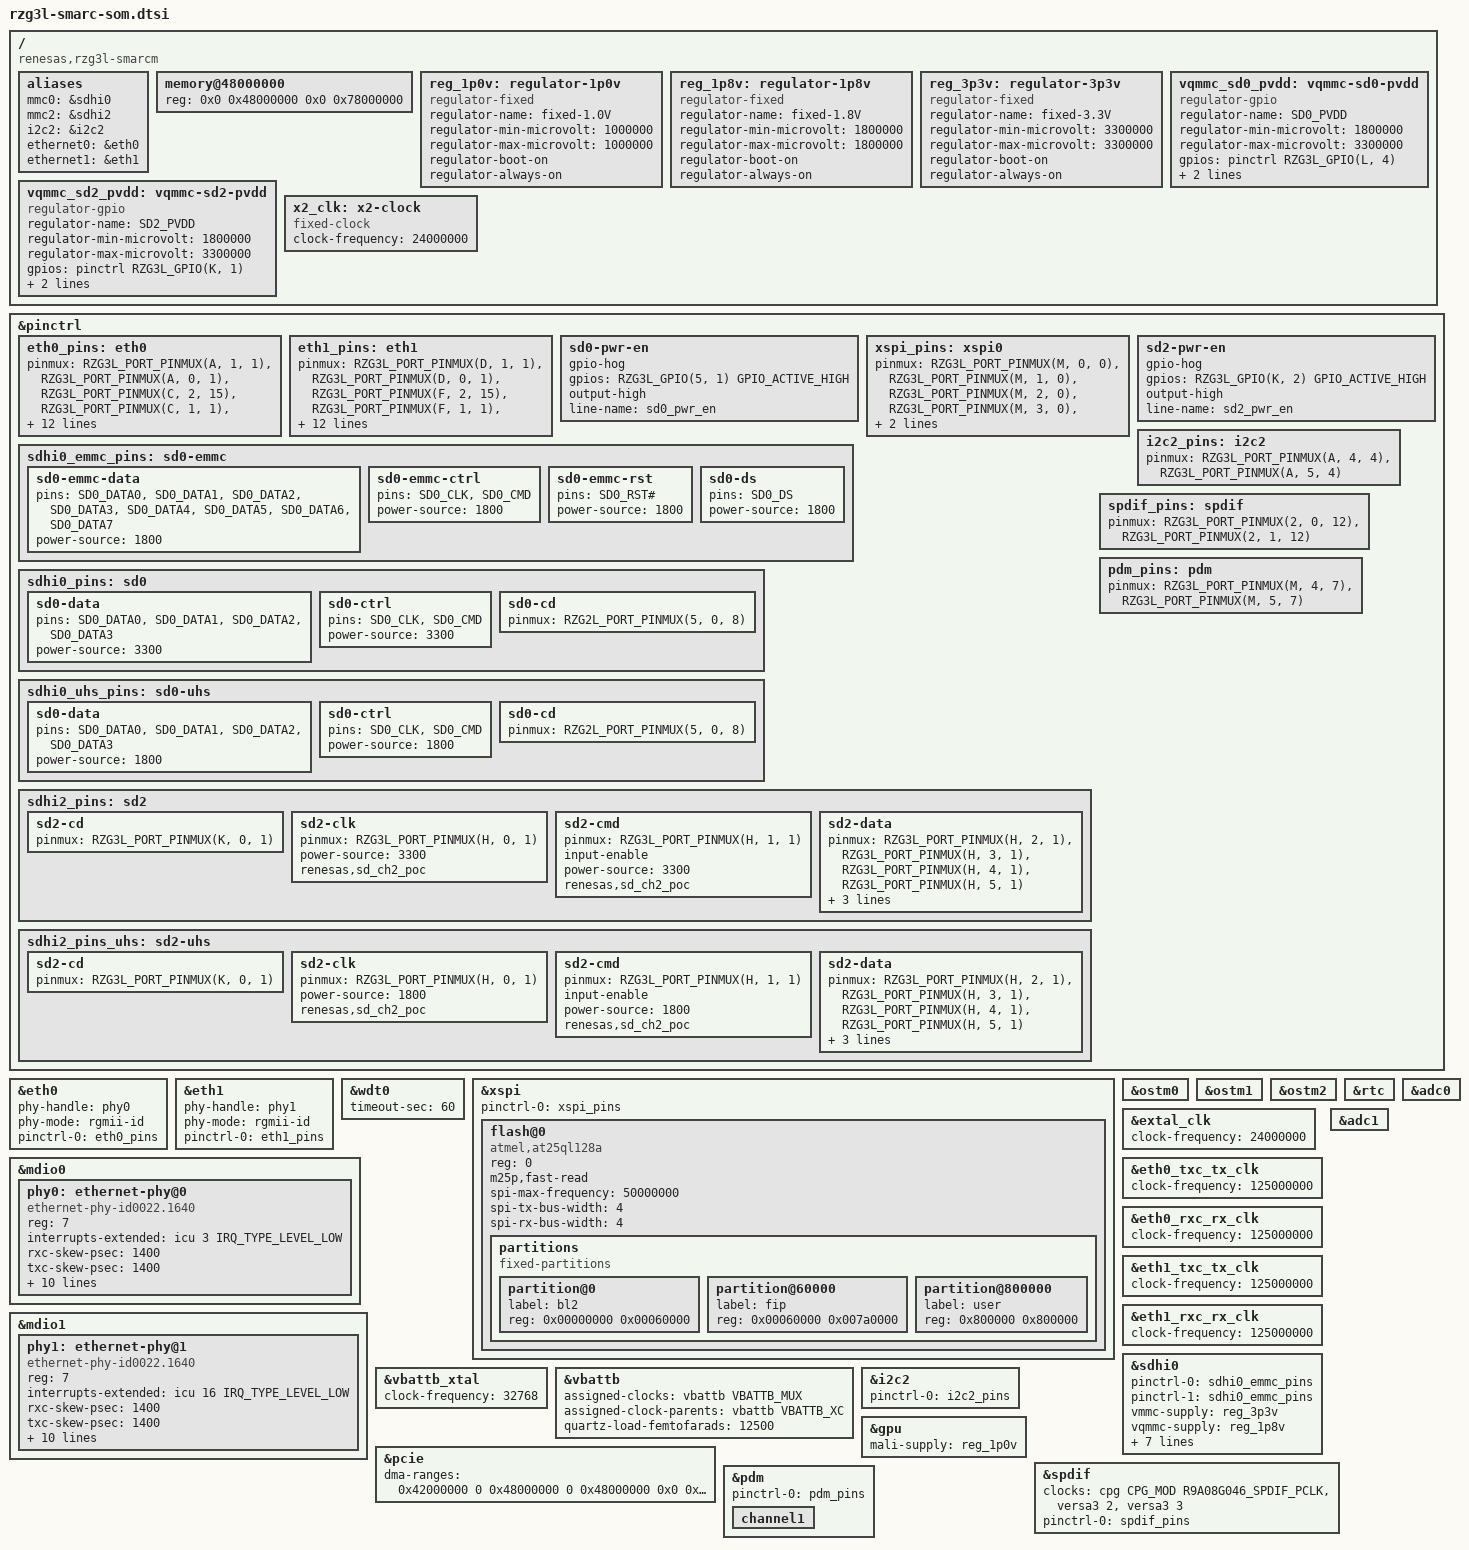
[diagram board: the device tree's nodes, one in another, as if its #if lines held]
// SPDX-License-Identifier: (GPL-2.0-only OR BSD-2-Clause)
/*
 * Device Tree Source for R9A08G046L68 SMARC SoM board.
 *
 * Copyright (C) 2025 Renesas Electronics Corp.
 */

/*
 * Please set the below switch position on the SoM and the corresponding macro
 * on the board DTS:
 *
 * Switch position SYS.1, Macro SW_SD0_DEV_SEL:
 *      0 - SD0 is connected to eMMC (default)
 *      1 - SD0 is connected to uSD0 card
 *
 * Switch position SYS.5, Macro SW_DPI_EN:
 *      0 - Select Misc. Signals routing
 *      1 - Select LCD
 */

#include <dt-bindings/clock/renesas,r9a08g046-vbattb.h>

/ {
	compatible = "renesas,rzg3l-smarcm", "renesas,r9a08g046l48", "renesas,r9a08g046";

	aliases {
		mmc0 = &sdhi0;
		mmc2 = &sdhi2;
		i2c2 = &i2c2;
		ethernet0 = &eth0;
		ethernet1 = &eth1;
	};

	memory@48000000 {
		device_type = "memory";
		/* First 128MB is reserved for secure area. */
		reg = <0x0 0x48000000 0x0 0x78000000>;
	};

	reg_1p0v: regulator-1p0v {
		compatible = "regulator-fixed";
		regulator-name = "fixed-1.0V";
		regulator-min-microvolt = <1000000>;
		regulator-max-microvolt = <1000000>;
		regulator-boot-on;
		regulator-always-on;
	};

	reg_1p8v: regulator-1p8v {
		compatible = "regulator-fixed";
		regulator-name = "fixed-1.8V";
		regulator-min-microvolt = <1800000>;
		regulator-max-microvolt = <1800000>;
		regulator-boot-on;
		regulator-always-on;
	};

	reg_3p3v: regulator-3p3v {
		compatible = "regulator-fixed";
		regulator-name = "fixed-3.3V";
		regulator-min-microvolt = <3300000>;
		regulator-max-microvolt = <3300000>;
		regulator-boot-on;
		regulator-always-on;
	};

#if SW_SD0_DEV_SEL
	vqmmc_sd0_pvdd: vqmmc-sd0-pvdd {
		compatible = "regulator-gpio";
		regulator-name = "SD0_PVDD";
		regulator-min-microvolt = <1800000>;
		regulator-max-microvolt = <3300000>;
		gpios = <&pinctrl RZG3L_GPIO(L, 4) GPIO_ACTIVE_HIGH>;
		gpios-states = <0>;
		states = <3300000 0>, <1800000 1>;
	};
#endif

#if SW_SD2_DEV_SEL
        vqmmc_sd2_pvdd: vqmmc-sd2-pvdd {
		compatible = "regulator-gpio";
		regulator-name = "SD2_PVDD";
		regulator-min-microvolt = <1800000>;
		regulator-max-microvolt = <3300000>;
		gpios = <&pinctrl RZG3L_GPIO(K, 1) GPIO_ACTIVE_HIGH>;
		gpios-states = <0>;
		states = <3300000 0>, <1800000 1>;
	};
#endif

	x2_clk: x2-clock {
		compatible = "fixed-clock";
		#clock-cells = <0>;
		clock-frequency = <24000000>;
	};
};

&pinctrl {
	eth0_pins: eth0 {
		pinmux = <RZG3L_PORT_PINMUX(A, 1, 1)>, /* MDC */
			 <RZG3L_PORT_PINMUX(A, 0, 1)>, /* MDIO */
			 <RZG3L_PORT_PINMUX(C, 2, 15)>, /* PHY_INTR */
			 <RZG3L_PORT_PINMUX(C, 1, 1)>, /* RXD3 */
			 <RZG3L_PORT_PINMUX(C, 0, 1)>, /* RXD2 */
			 <RZG3L_PORT_PINMUX(B, 7, 1)>, /* RXD1 */
			 <RZG3L_PORT_PINMUX(B, 6, 1)>, /* RXD0 */
			 <RZG3L_PORT_PINMUX(B, 0, 1)>, /* RXC */
			 <RZG3L_PORT_PINMUX(A, 2, 1)>, /* RX_CTL */
			 <RZG3L_PORT_PINMUX(B, 5, 1)>, /* TXD3 */
			 <RZG3L_PORT_PINMUX(B, 4, 1)>, /* TXD2 */
			 <RZG3L_PORT_PINMUX(B, 3, 1)>, /* TXD1 */
			 <RZG3L_PORT_PINMUX(B, 2, 1)>, /* TXD0 */
			 <RZG3L_PORT_PINMUX(B, 1, 1)>, /* TXC */
			 <RZG3L_PORT_PINMUX(A, 3, 1)>; /* TX_CTL */
			 power-source = <1800>;
	};

	eth1_pins: eth1 {
		pinmux = <RZG3L_PORT_PINMUX(D, 1, 1)>, /* MDC */
			 <RZG3L_PORT_PINMUX(D, 0, 1)>, /* MDIO */
			 <RZG3L_PORT_PINMUX(F, 2, 15)>, /* PHY_INTR */
			 <RZG3L_PORT_PINMUX(F, 1, 1)>, /* RXD3 */
			 <RZG3L_PORT_PINMUX(F, 0, 1)>, /* RXD2 */
			 <RZG3L_PORT_PINMUX(E, 7, 1)>, /* RXD1 */
			 <RZG3L_PORT_PINMUX(E, 6, 1)>, /* RXD0 */
			 <RZG3L_PORT_PINMUX(E, 0, 1)>, /* RXC */
			 <RZG3L_PORT_PINMUX(D, 2, 1)>, /* RX_CTL */
			 <RZG3L_PORT_PINMUX(E, 5, 1)>, /* TXD3 */
			 <RZG3L_PORT_PINMUX(E, 4, 1)>, /* TXD2 */
			 <RZG3L_PORT_PINMUX(E, 3, 1)>, /* TXD1 */
			 <RZG3L_PORT_PINMUX(E, 2, 1)>, /* TXD0 */
			 <RZG3L_PORT_PINMUX(E, 1, 1)>, /* TXC */
			 <RZG3L_PORT_PINMUX(D, 3, 1)>; /* TX_CTL */
			 power-source = <1800>;
	};

#if (!SW_DPI_EN)
	sd0-pwr-en {
		gpio-hog;
		gpios = <RZG3L_GPIO(5, 1) GPIO_ACTIVE_HIGH>;
		output-high;
		line-name = "sd0_pwr_en";
	};
#endif

	xspi_pins: xspi0 {
		pinmux = <RZG3L_PORT_PINMUX(M, 0, 0)>, /* XSPI0_IO0 */
			 <RZG3L_PORT_PINMUX(M, 1, 0)>, /* XSPI0_IO1 */
			 <RZG3L_PORT_PINMUX(M, 2, 0)>, /* XSPI0_IO2 */
			 <RZG3L_PORT_PINMUX(M, 3, 0)>, /* XSPI0_IO3 */
			 <RZG3L_PORT_PINMUX(L, 0, 0)>, /* XSPI0_CKP */
			 <RZG3L_PORT_PINMUX(L, 1, 0)>; /* XSPI0_CS0 */
	};

	sdhi0_emmc_pins: sd0-emmc {
		sd0-emmc-data {
			pins = "SD0_DATA0", "SD0_DATA1", "SD0_DATA2", "SD0_DATA3",
			       "SD0_DATA4", "SD0_DATA5", "SD0_DATA6", "SD0_DATA7";
			power-source = <1800>;
		};

		sd0-emmc-ctrl {
			pins = "SD0_CLK", "SD0_CMD";
			power-source = <1800>;
		};

		sd0-emmc-rst {
			pins = "SD0_RST#";
			power-source = <1800>;
		};

		sd0-ds {
			pins = "SD0_DS";
			power-source = <1800>;
		};
	};

	sdhi0_pins: sd0 {
		sd0-data {
			pins = "SD0_DATA0", "SD0_DATA1", "SD0_DATA2", "SD0_DATA3";
			power-source = <3300>;
		};

		sd0-ctrl {
			pins = "SD0_CLK", "SD0_CMD";
			power-source = <3300>;
		};

		sd0-cd {
			pinmux = <RZG2L_PORT_PINMUX(5, 0, 8)>; /* SD0_CD */
		};
	};

	sdhi0_uhs_pins: sd0-uhs {
		sd0-data {
			pins = "SD0_DATA0", "SD0_DATA1", "SD0_DATA2", "SD0_DATA3";
			power-source = <1800>;
		};

		sd0-ctrl {
			pins = "SD0_CLK", "SD0_CMD";
			power-source = <1800>;
		};

		sd0-cd {
			pinmux = <RZG2L_PORT_PINMUX(5, 0, 8)>; /* SD0_CD */
		};
	};

#if (SW_SD2_DEV_SEL)
	sd2-pwr-en {
		gpio-hog;
		gpios = <RZG3L_GPIO(K, 2) GPIO_ACTIVE_HIGH>;
		output-high;
		line-name = "sd2_pwr_en";
	};

	sdhi2_pins: sd2 {
		sd2-cd {
			pinmux = <RZG3L_PORT_PINMUX(K, 0, 1)>; /* SD2_CD */
		};

		sd2-clk {
			pinmux = <RZG3L_PORT_PINMUX(H, 0, 1)>; /* SD2_CLK */
			power-source = <3300>;
			renesas,sd_ch2_poc;
		};

		sd2-cmd {
			pinmux = <RZG3L_PORT_PINMUX(H, 1, 1)>; /* SD2_CMD */
			input-enable;
			power-source = <3300>;
			renesas,sd_ch2_poc;
		};

		sd2-data {
			pinmux = <RZG3L_PORT_PINMUX(H, 2, 1)>, /* SD2_DAT0 */
				 <RZG3L_PORT_PINMUX(H, 3, 1)>, /* SD2_DAT1 */
				 <RZG3L_PORT_PINMUX(H, 4, 1)>, /* SD2_DAT2 */
				 <RZG3L_PORT_PINMUX(H, 5, 1)>; /* SD2_DAT3 */
			input-enable;
			power-source = <3300>;
			renesas,sd_ch2_poc;
		};
	};

	sdhi2_pins_uhs: sd2-uhs {
		sd2-cd {
			pinmux = <RZG3L_PORT_PINMUX(K, 0, 1)>; /* SD2_CD */
		};

		sd2-clk {
			pinmux = <RZG3L_PORT_PINMUX(H, 0, 1)>; /* SD2_CLK */
			power-source = <1800>;
			renesas,sd_ch2_poc;
		};

		sd2-cmd {
			pinmux = <RZG3L_PORT_PINMUX(H, 1, 1)>; /* SD2_CMD */
			input-enable;
			power-source = <1800>;
			renesas,sd_ch2_poc;
		};

		sd2-data {
			pinmux = <RZG3L_PORT_PINMUX(H, 2, 1)>, /* SD2_DAT0 */
				 <RZG3L_PORT_PINMUX(H, 3, 1)>, /* SD2_DAT1 */
				 <RZG3L_PORT_PINMUX(H, 4, 1)>, /* SD2_DAT2 */
				 <RZG3L_PORT_PINMUX(H, 5, 1)>; /* SD2_DAT3 */
			input-enable;
			power-source = <1800>;
			renesas,sd_ch2_poc;
		};
	};
#endif

	i2c2_pins: i2c2 {
		pinmux = <RZG3L_PORT_PINMUX(A, 4, 4)>, /* SCL */
			 <RZG3L_PORT_PINMUX(A, 5, 4)>; /* SDA */
	};

#if (SPDIF_SEL)
	spdif_pins: spdif {
		pinmux = <RZG3L_PORT_PINMUX(2, 0, 12)>, /* SPDIF_IN */
			 <RZG3L_PORT_PINMUX(2, 1, 12)>; /* SPDIF_OUT */
	};
#endif

	pdm_pins: pdm {
		pinmux = <RZG3L_PORT_PINMUX(M, 4, 7)>, /* CLK1 */
			 <RZG3L_PORT_PINMUX(M, 5, 7)>; /* DAT1 */
	};
};

&eth0 {
	phy-handle = <&phy0>;
	phy-mode = "rgmii-id";

	pinctrl-0 = <&eth0_pins>;
	pinctrl-names = "default";
	status = "okay";
};

&eth1 {
	phy-handle = <&phy1>;
	phy-mode = "rgmii-id";

	pinctrl-0 = <&eth1_pins>;
	pinctrl-names = "default";
	status = "okay";
};

&wdt0 {
	timeout-sec = <60>;
	status = "okay";
};

&xspi {
	pinctrl-0 = <&xspi_pins>;
	pinctrl-names = "default";

	status = "okay";

	flash@0 {
		compatible = "atmel,at25ql128a", "jedec,spi-nor";
		reg = <0>;
		m25p,fast-read;
		spi-max-frequency = <50000000>;
		spi-tx-bus-width = <4>;
		spi-rx-bus-width = <4>;

		partitions {
			compatible = "fixed-partitions";
			#address-cells = <1>;
			#size-cells = <1>;

			partition@0 {
				label = "bl2";
				reg = <0x00000000 0x00060000>;
			};

			partition@60000 {
				label = "fip";
				reg = <0x00060000 0x007a0000>;
			};

			partition@800000 {
				label = "user";
				reg = <0x800000 0x800000>;
			};
		};
	};
};

&ostm0 {
	status = "okay";
};

&ostm1 {
	status = "okay";
};

&ostm2 {
	status = "okay";
};

&mdio0 {
	phy0: ethernet-phy@0 {
		compatible = "ethernet-phy-id0022.1640", "ethernet-phy-ieee802.3-c22";
		reg = <7>;
		interrupts-extended = <&icu 3 IRQ_TYPE_LEVEL_LOW>;
		rxc-skew-psec = <1400>;
		txc-skew-psec = <1400>;
		rxdv-skew-psec = <0>;
		txdv-skew-psec = <0>;
		rxd0-skew-psec = <0>;
		rxd1-skew-psec = <0>;
		rxd2-skew-psec = <0>;
		rxd3-skew-psec = <0>;
		txd0-skew-psec = <0>;
		txd1-skew-psec = <0>;
		txd2-skew-psec = <0>;
		txd3-skew-psec = <0>;
	};
};

&mdio1 {
	phy1: ethernet-phy@1 {
		compatible = "ethernet-phy-id0022.1640", "ethernet-phy-ieee802.3-c22";
		reg = <7>;
		interrupts-extended = <&icu 16 IRQ_TYPE_LEVEL_LOW>;
		rxc-skew-psec = <1400>;
		txc-skew-psec = <1400>;
		rxdv-skew-psec = <0>;
		txdv-skew-psec = <0>;
		rxd0-skew-psec = <0>;
		rxd1-skew-psec = <0>;
		rxd2-skew-psec = <0>;
		rxd3-skew-psec = <0>;
		txd0-skew-psec = <0>;
		txd1-skew-psec = <0>;
		txd2-skew-psec = <0>;
		txd3-skew-psec = <0>;
	};
};

&extal_clk {
	clock-frequency = <24000000>;
};

&eth0_txc_tx_clk {
	clock-frequency = <125000000>;
};

&eth0_rxc_rx_clk {
	clock-frequency = <125000000>;
};

&eth1_txc_tx_clk {
	clock-frequency = <125000000>;
};

&eth1_rxc_rx_clk {
	clock-frequency = <125000000>;
};

#if (!SW_SD0_DEV_SEL) /* eMMC */
&sdhi0 {
	pinctrl-0 = <&sdhi0_emmc_pins>;
	pinctrl-1 = <&sdhi0_emmc_pins>;
	pinctrl-names = "default", "state_uhs";

	vmmc-supply = <&reg_3p3v>;
	vqmmc-supply = <&reg_1p8v>;
	bus-width = <8>;
	mmc-hs200-1_8v;
	mmc-hs400-1_8v;
	mmc-hs400-enhanced-strobe;
	non-removable;
	fixed-emmc-driver-type = <1>;
	max-frequency = <300000000>;
	status = "okay";
};
#else /* SD0 slot */
&sdhi0 {
	pinctrl-0 = <&sdhi0_pins>;
	pinctrl-1 = <&sdhi0_uhs_pins>;
	pinctrl-names = "default", "state_uhs";
	vmmc-supply = <&reg_3p3v>;
	vqmmc-supply = <&vqmmc_sd0_pvdd>;
	bus-width = <4>;
	sd-uhs-sdr50;
	sd-uhs-sdr104;
	max-frequency = <125000000>;
	status = "okay";
};
#endif

&vbattb_xtal {
	clock-frequency = <32768>;
};

&vbattb {
	assigned-clocks = <&vbattb VBATTB_MUX>;
#if (SOSEL_XC)
	assigned-clock-parents = <&vbattb VBATTB_XC>;
#else
	assigned-clock-parents = <&vbattb VBATTB_XBYP>;
#endif
	quartz-load-femtofarads = <12500>;
	status = "okay";
};

&rtc {
	status = "okay";
};

&pcie {
	/* First 128MB is reserved for secure area. */
	dma-ranges = <0x42000000 0 0x48000000 0 0x48000000 0x0 0x38000000>;
};

&adc0 {
	status = "okay";
};

&adc1 {
	status = "okay";
};

&i2c2 {
	pinctrl-0 = <&i2c2_pins>;
	pinctrl-names = "default";

	status = "okay";
};

&gpu {
	status = "okay";
	mali-supply = <&reg_1p0v>;
};

#if (SPDIF_SEL)
&spdif {
	clocks = <&cpg CPG_MOD R9A08G046_SPDIF_PCLK>,
		 <&versa3 2>, <&versa3 3>;
	pinctrl-names = "default";
	pinctrl-0 = <&spdif_pins>;

	status = "okay";
};
#endif

&pdm {
	pinctrl-0 = <&pdm_pins>;
	pinctrl-names = "default";
	status = "okay";

	channel1 {
		status = "okay";
	};
};
